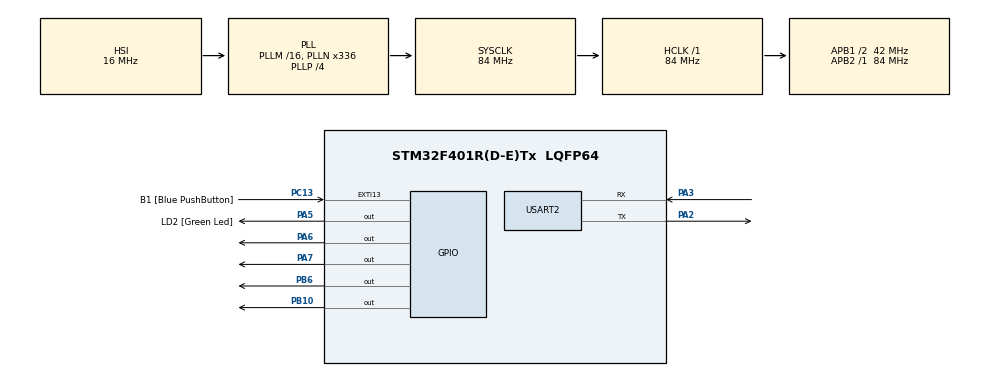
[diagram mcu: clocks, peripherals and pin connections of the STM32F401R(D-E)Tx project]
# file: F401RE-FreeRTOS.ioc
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FREERTOS.Tasks01=LD1Task,24,128,StartTask1,Default,NULL,Dynamic,NULL,NULL;LE2Task02,8,128,StartTask02,Default,NULL,Dynamic,NULL,NULL;LD3Task03,8,128,StartTask03,Default,NULL,Dynamic,NULL,NULL
FREERTOS.configUSE_NEWLIB_REENTRANT=1
Mcu.Family=STM32F4
Mcu.Name=STM32F401R(D-E)Tx
Mcu.Package=LQFP64
NVIC.PriorityGroup=NVIC_PRIORITYGROUP_4
NVIC.TIM4_IRQn=true\:15\:0\:false\:false\:true\:false\:false\:true\:true
NVIC.TimeBase=TIM4_IRQn
NVIC.TimeBaseIP=TIM4
PA13.Mode=Serial_Wire
PA13.Signal=SYS_JTMS-SWDIO
PA14.Mode=Serial_Wire
PA14.Signal=SYS_JTCK-SWCLK
PA2.Mode=Asynchronous
PA2.Signal=USART2_TX
PA3.Mode=Asynchronous
PA3.Signal=USART2_RX
PA5.GPIO_Label=LD2 [Green Led]
PA5.GPIO_Mode=GPIO_MODE_OUTPUT_PP
PA5.GPIO_PuPd=GPIO_NOPULL
PA5.GPIO_Speed=GPIO_SPEED_FREQ_LOW
PA5.Signal=GPIO_Output
PA6.Signal=GPIO_Output
PA7.Signal=GPIO_Output
PB10.Signal=GPIO_Output
PB6.Signal=GPIO_Output
PC13-ANTI_TAMP.GPIO_Label=B1 [Blue PushButton]
PC13-ANTI_TAMP.GPIO_ModeDefaultEXTI=GPIO_MODE_IT_FALLING
PC13-ANTI_TAMP.GPIO_PuPd=GPIO_NOPULL
PC13-ANTI_TAMP.Signal=GPXTI13
PC14-OSC32_IN.Mode=LSE-External-Oscillator
PC14-OSC32_IN.Signal=RCC_OSC32_IN
PC15-OSC32_OUT.Mode=LSE-External-Oscillator
PC15-OSC32_OUT.Signal=RCC_OSC32_OUT
PH0\ -\ OSC_IN.Mode=HSE-External-Oscillator
PH0\ -\ OSC_IN.Signal=RCC_OSC_IN
PH1\ -\ OSC_OUT.Mode=HSE-External-Oscillator
PH1\ -\ OSC_OUT.Signal=RCC_OSC_OUT
ProjectManager.HeapSize=0x200
ProjectManager.StackSize=0x400
ProjectManager.TargetToolchain=STM32CubeIDE
RCC.48MHZClocksFreq_Value=48000000
RCC.AHBFreq_Value=84000000
RCC.APB1CLKDivider=RCC_HCLK_DIV2
RCC.APB1Freq_Value=42000000
RCC.APB1TimFreq_Value=84000000
RCC.APB2Freq_Value=84000000
RCC.APB2TimFreq_Value=84000000
RCC.CortexFreq_Value=84000000
RCC.HCLKFreq_Value=84000000
RCC.HSE_VALUE=8000000
RCC.HSI_VALUE=16000000
RCC.PLLN=336
RCC.PLLP=RCC_PLLP_DIV4
RCC.PLLQ=7
RCC.SYSCLKFreq_VALUE=84000000
RCC.SYSCLKSource=RCC_SYSCLKSOURCE_PLLCLK
RCC.VCOOutputFreq_Value=336000000
USART2.VirtualMode=VM_ASYNC
VP_FREERTOS_VS_CMSIS_V2.Mode=CMSIS_V2
VP_SYS_VS_tim4.Mode=TIM4
board=NUCLEO-F401RE

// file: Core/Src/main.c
/* USER CODE BEGIN Header */
/**
  ******************************************************************************
  * @file           : main.c
  * @brief          : Main program body
  ******************************************************************************
  * @attention
  *
  * Copyright (c) 2023 STMicroelectronics.
  * All rights reserved.
  *
  * This software is licensed under terms that can be found in the LICENSE file
  * in the root directory of this software component.
  * If no LICENSE file comes with this software, it is provided AS-IS.
  *
  ******************************************************************************
  */
/* USER CODE END Header */
#include "main.h"
#include "cmsis_os.h"
#include "usart.h"
#include "gpio.h"

/* USER CODE BEGIN Includes */
#include <stdio.h>
/* USER CODE END Includes */

void SystemClock_Config(void);
void MX_FREERTOS_Init(void);

/* USER CODE BEGIN 0 */
int __io_putchar(int ch){
	HAL_UART_Transmit(&huart2, (uint8_t *)&ch, sizeof(ch), 1000);
	return ch;
}
/* USER CODE END 0 */

int main(void)
{

  /* MCU Configuration--------------------------------------------------------*/

  /* Reset of all peripherals, Initializes the Flash interface and the Systick. */
  HAL_Init();

  /* Configure the system clock */
  SystemClock_Config();

  /* Initialize all configured peripherals */
  MX_GPIO_Init();
  MX_USART2_UART_Init();

  /* Init scheduler */
  osKernelInitialize();  /* Call init function for freertos objects (in freertos.c) */
  MX_FREERTOS_Init();

  /* Start scheduler */
  osKernelStart();

  /* We should never get here as control is now taken by the scheduler */
  /* Infinite loop */
  while (1)
  {

  }
}

void SystemClock_Config(void)
{
  RCC_OscInitTypeDef RCC_OscInitStruct = {0};
  RCC_ClkInitTypeDef RCC_ClkInitStruct = {0};

  /** Configure the main internal regulator output voltage
  */
  __HAL_RCC_PWR_CLK_ENABLE();
  __HAL_PWR_VOLTAGESCALING_CONFIG(PWR_REGULATOR_VOLTAGE_SCALE2);

  /** Initializes the RCC Oscillators according to the specified parameters
  * in the RCC_OscInitTypeDef structure.
  */
  RCC_OscInitStruct.OscillatorType = RCC_OSCILLATORTYPE_HSI;
  RCC_OscInitStruct.HSIState = RCC_HSI_ON;
  RCC_OscInitStruct.HSICalibrationValue = RCC_HSICALIBRATION_DEFAULT;
  RCC_OscInitStruct.PLL.PLLState = RCC_PLL_ON;
  RCC_OscInitStruct.PLL.PLLSource = RCC_PLLSOURCE_HSI;
  RCC_OscInitStruct.PLL.PLLM = 16;
  RCC_OscInitStruct.PLL.PLLN = 336;
  RCC_OscInitStruct.PLL.PLLP = RCC_PLLP_DIV4;
  RCC_OscInitStruct.PLL.PLLQ = 7;
  if (HAL_RCC_OscConfig(&RCC_OscInitStruct) != HAL_OK)
  {
    Error_Handler();
  }

  /** Initializes the CPU, AHB and APB buses clocks
  */
  RCC_ClkInitStruct.ClockType = RCC_CLOCKTYPE_HCLK|RCC_CLOCKTYPE_SYSCLK
                              |RCC_CLOCKTYPE_PCLK1|RCC_CLOCKTYPE_PCLK2;
  RCC_ClkInitStruct.SYSCLKSource = RCC_SYSCLKSOURCE_PLLCLK;
  RCC_ClkInitStruct.AHBCLKDivider = RCC_SYSCLK_DIV1;
  RCC_ClkInitStruct.APB1CLKDivider = RCC_HCLK_DIV2;
  RCC_ClkInitStruct.APB2CLKDivider = RCC_HCLK_DIV1;

  if (HAL_RCC_ClockConfig(&RCC_ClkInitStruct, FLASH_LATENCY_2) != HAL_OK)
  {
    Error_Handler();
  }
}

void HAL_TIM_PeriodElapsedCallback(TIM_HandleTypeDef *htim)
{
  if (htim->Instance == TIM4) {
    HAL_IncTick();
  }
}

void Error_Handler(void)
{
  __disable_irq();
  while (1)
  {
  }
}

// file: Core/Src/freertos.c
/* USER CODE BEGIN Header */
/**
  ******************************************************************************
  * File Name          : freertos.c
  * Description        : Code for freertos applications
  ******************************************************************************
  * @attention
  *
  * Copyright (c) 2023 STMicroelectronics.
  * All rights reserved.
  *
  * This software is licensed under terms that can be found in the LICENSE file
  * in the root directory of this software component.
  * If no LICENSE file comes with this software, it is provided AS-IS.
  *
  ******************************************************************************
  */
/* USER CODE END Header */

#include "FreeRTOS.h"
#include "task.h"
#include "main.h"
#include "cmsis_os.h"

/* Definitions for LD1Task */
osThreadId_t LD1TaskHandle;
const osThreadAttr_t LD1Task_attributes = {
  .name = "LD1Task",
  .stack_size = 128 * 4,
  .priority = (osPriority_t) osPriorityNormal,
};
/* Definitions for LE2Task02 */
osThreadId_t LE2Task02Handle;
const osThreadAttr_t LE2Task02_attributes = {
  .name = "LE2Task02",
  .stack_size = 128 * 4,
  .priority = (osPriority_t) osPriorityLow,
};
/* Definitions for LD3Task03 */
osThreadId_t LD3Task03Handle;
const osThreadAttr_t LD3Task03_attributes = {
  .name = "LD3Task03",
  .stack_size = 128 * 4,
  .priority = (osPriority_t) osPriorityLow,
};

void StartTask1(void *argument);
void StartTask02(void *argument);
void StartTask03(void *argument);

void MX_FREERTOS_Init(void); /* (MISRA C 2004 rule 8.1) */

void MX_FREERTOS_Init(void) {

  /* Create the thread(s) */
  /* creation of LD1Task */
  LD1TaskHandle = osThreadNew(StartTask1, NULL, &LD1Task_attributes);

  /* creation of LE2Task02 */
  LE2Task02Handle = osThreadNew(StartTask02, NULL, &LE2Task02_attributes);

  /* creation of LD3Task03 */
  LD3Task03Handle = osThreadNew(StartTask03, NULL, &LD3Task03_attributes);

}

void StartTask1(void *argument)
{
  /* USER CODE BEGIN StartTask1 */
  /* Infinite loop */
  for(;;)
  {
	  HAL_GPIO_TogglePin(GPIOA, GPIO_PIN_6);
	  printf("TASK1-0.1\r\n");
	  osDelay(100);
  }
  /* USER CODE END StartTask1 */
}

void StartTask02(void *argument)
{
  /* USER CODE BEGIN StartTask02 */
  /* Infinite loop */
  for(;;)
  {
	  HAL_GPIO_TogglePin(GPIOA, GPIO_PIN_7);
	  printf("TASK2-0.5\r\n");
	  osDelay(500);
  }
  /* USER CODE END StartTask02 */
}

void StartTask03(void *argument)
{
  /* USER CODE BEGIN StartTask03 */
  /* Infinite loop */
  for(;;)
  {
	  HAL_GPIO_TogglePin(GPIOB, GPIO_PIN_6);
	  printf("TASK3-1\r\n");
	  osDelay(1000);
  }
  /* USER CODE END StartTask03 */
}
